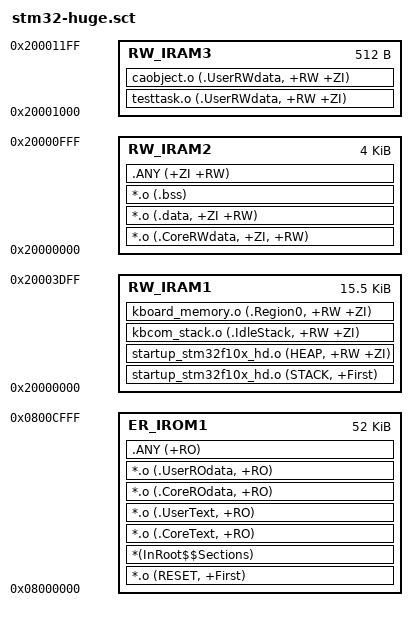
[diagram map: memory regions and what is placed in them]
; *************************************************************
; *** Scatter-Loading Description File generated by uVision ***
; *************************************************************

LR_IROM1 0x08000000 0x0000D000  {    ; load region size_region
  ER_IROM1 0x08000000 0x0000D000  {  ; load address = execution address
   *.o (RESET, +First)
   *(InRoot$$Sections)
   *.o (.CoreText, +RO)
   *.o (.UserText, +RO)
   *.o (.CoreROdata, +RO)
   *.o (.UserROdata, +RO)
   .ANY (+RO)
  }

  RW_IRAM1 0x20000000 0x00003e00  {  ; RW data
   startup_stm32f10x_hd.o (STACK, +First)
   startup_stm32f10x_hd.o (HEAP, +RW +ZI)
   kbcom_stack.o (.IdleStack, +RW +ZI)
   kboard_memory.o (.Region0, +RW +ZI)
;   kbstm32_stack.o (.CoreStack, +RW +ZI)
  }

  RW_IRAM2 0x20000000 0x00001000  {  ; RW data
   *.o (.CoreRWdata, +ZI, +RW)
   *.o (.data, +ZI +RW)
   *.o (.bss)
   .ANY (+ZI +RW)
  }
  RW_IRAM3 0x20001000 0x00000200  {  ; RW data
   testtask.o (.UserRWdata, +RW +ZI)
   caobject.o (.UserRWdata, +RW +ZI)
  }
}

